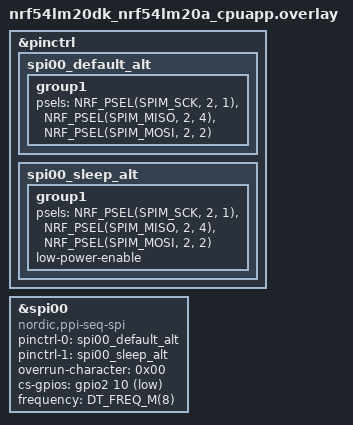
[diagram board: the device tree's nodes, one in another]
/*
 * Copyright (c) 2026 Nordic Semiconductor ASA
 *
 * SPDX-License-Identifier: LicenseRef-Nordic-5-Clause
 */

&pinctrl {
	spi00_default_alt: spi00_default_alt {
		group1 {
			psels = <NRF_PSEL(SPIM_SCK, 2, 1)>,
				<NRF_PSEL(SPIM_MISO, 2, 4)>,
				<NRF_PSEL(SPIM_MOSI, 2, 2)>;
		};
	};

	spi00_sleep_alt: spi00_sleep_alt {
		group1 {
			psels = <NRF_PSEL(SPIM_SCK, 2, 1)>,
				<NRF_PSEL(SPIM_MISO, 2, 4)>,
				<NRF_PSEL(SPIM_MOSI, 2, 2)>;
			low-power-enable;
		};
	};
};

/delete-node/ &mx25r64;

sample_spi: &spi00 {
	compatible = "nordic,ppi-seq-spi";
	status = "okay";
	pinctrl-0 = <&spi00_default_alt>;
	pinctrl-1 = <&spi00_sleep_alt>;
	pinctrl-names = "default", "sleep";
	overrun-character = <0x00>;
	cs-gpios = <&gpio2 10 GPIO_ACTIVE_LOW>;
	frequency = <DT_FREQ_M(8)>;
};
